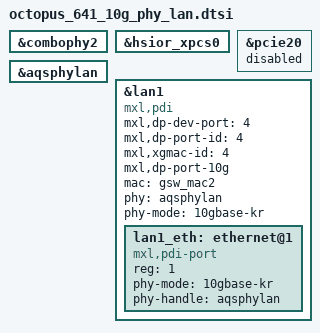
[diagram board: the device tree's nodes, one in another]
// SPDX-License-Identifier: GPL-2.0
/*
 * Copyright (C) 2023 MaxLinear, Inc.
 */

/* combo phy 2 */
&combophy2 { /* PCIe20/21, HSIOR_XPCS0/1, SATA20/21 */
	status = "okay";
};

&hsior_xpcs0 {
	status = "okay";
};

&pcie20 {
	status = "disabled";
};

&aqsphylan {
	status = "okay";
};

&lan1 {
	status = "okay";

	#address-cells = <1>;
	#size-cells = <0>;

	compatible = "mxl,pdi";
	mxl,dp-dev-port = <4>;
	mxl,dp-port-id = <4>;
	mxl,xgmac-id = <4>;
	mxl,dp-port-10g;
	mac = <&gsw_mac2>;
	phy = <&aqsphylan>;
	phy-mode = "10gbase-kr";

	lan1_eth: ethernet@1 {
		compatible = "mxl,pdi-port";
		reg = <1>;
		phy-mode = "10gbase-kr";
		phy-handle = <&aqsphylan>;
	};
};
